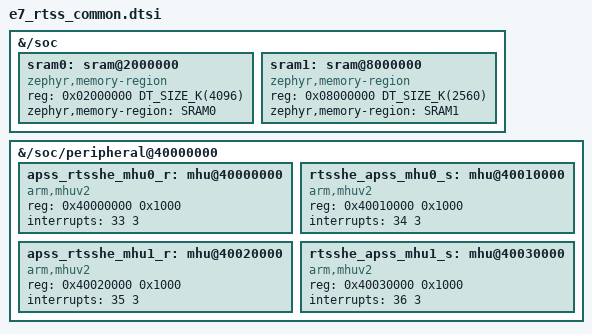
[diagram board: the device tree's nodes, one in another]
/* Copyright (c) 2024 Alif Semiconductor
 *
 * SPDX-License-Identifier: Apache-2.0
 */
#include "ensemble_rtss_common.dtsi"

&{/soc} {
	sram0: sram@2000000 {
		compatible = "zephyr,memory-region","mmio-sram";
		reg = <0x02000000 DT_SIZE_K(4096)>;
		zephyr,memory-region = "SRAM0";
	};
	sram1: sram@8000000 {
		compatible = "zephyr,memory-region","mmio-sram";
		reg = <0x08000000 DT_SIZE_K(2560)>;
		zephyr,memory-region = "SRAM1";
	};
};

&{/soc/peripheral@40000000} {
	apss_rtsshe_mhu0_r: mhu@40000000 {
		compatible = "arm,mhuv2";
		reg = < 0x40000000 0x1000 >;
		interrupts = < 33 3 >;
		interrupt-names = "rx";
	};
	rtsshe_apss_mhu0_s: mhu@40010000 {
		compatible = "arm,mhuv2";
		reg = < 0x40010000 0x1000 >;
		interrupts = < 34 3 >;
		interrupt-names = "tx";
	};
	apss_rtsshe_mhu1_r: mhu@40020000 {
		compatible = "arm,mhuv2";
		reg = < 0x40020000 0x1000 >;
		interrupts = < 35 3 >;
		interrupt-names = "rx";
	};
	rtsshe_apss_mhu1_s: mhu@40030000 {
		compatible = "arm,mhuv2";
		reg = < 0x40030000 0x1000 >;
		interrupts = < 36 3 >;
		interrupt-names = "tx";
	};
};
